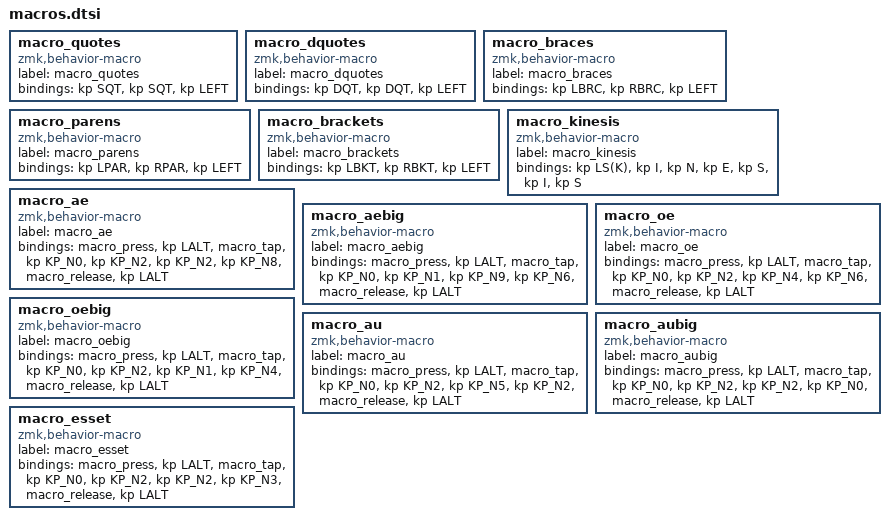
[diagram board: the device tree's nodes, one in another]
macro_quotes: macro_quotes{
compatible = "zmk,behavior-macro";
label = "macro_quotes";
#binding-cells = <0>;
bindings = <&kp SQT>, <&kp SQT>, <&kp LEFT>;
};
macro_dquotes: macro_dquotes{
compatible = "zmk,behavior-macro";
label = "macro_dquotes";
#binding-cells = <0>;
bindings = <&kp DQT>, <&kp DQT>, <&kp LEFT>;
};
macro_braces: macro_braces{
compatible = "zmk,behavior-macro";
label = "macro_braces";
#binding-cells = <0>;
bindings = <&kp LBRC>, <&kp RBRC>, <&kp LEFT>;
};
macro_parens: macro_parens{
compatible = "zmk,behavior-macro";
label = "macro_parens";
#binding-cells = <0>;
bindings = <&kp LPAR>, <&kp RPAR>, <&kp LEFT>;
};
macro_brackets: macro_brackets{
compatible = "zmk,behavior-macro";
label = "macro_brackets";
#binding-cells = <0>;
bindings = <&kp LBKT>, <&kp RBKT>, <&kp LEFT>;
};
macro_kinesis: macro_kinesis{
compatible = "zmk,behavior-macro";
label = "macro_kinesis";
#binding-cells = <0>;
bindings = <&kp LS(K)>, <&kp I>, <&kp N>, <&kp E>, <&kp S>, <&kp I>, <&kp S>;
};
macro_ae: macro_ae{
compatible = "zmk,behavior-macro";
label = "macro_ae";
#binding-cells = <0>;
bindings = <&macro_press &kp LALT>, <&macro_tap &kp KP_N0 &kp KP_N2 &kp KP_N2 &kp KP_N8>, <&macro_release &kp LALT>;
};
macro_aebig: macro_aebig{
compatible = "zmk,behavior-macro";
label = "macro_aebig";
#binding-cells = <0>;
bindings = <&macro_press &kp LALT>, <&macro_tap &kp KP_N0 &kp KP_N1 &kp KP_N9 &kp KP_N6>, <&macro_release &kp LALT>;
};
macro_oe: macro_oe{
compatible = "zmk,behavior-macro";
label = "macro_oe";
#binding-cells = <0>;
bindings = <&macro_press &kp LALT>, <&macro_tap &kp KP_N0 &kp KP_N2 &kp KP_N4 &kp KP_N6>, <&macro_release &kp LALT>;
};
macro_oebig: macro_oebig{
compatible = "zmk,behavior-macro";
label = "macro_oebig";
#binding-cells = <0>;
bindings = <&macro_press &kp LALT>, <&macro_tap &kp KP_N0 &kp KP_N2 &kp KP_N1 &kp KP_N4>, <&macro_release &kp LALT>;
};
macro_au: macro_au{
compatible = "zmk,behavior-macro";
label = "macro_au";
#binding-cells = <0>;
bindings = <&macro_press &kp LALT>, <&macro_tap &kp KP_N0 &kp KP_N2 &kp KP_N5 &kp KP_N2>, <&macro_release &kp LALT>;
};
macro_aubig: macro_aubig{
compatible = "zmk,behavior-macro";
label = "macro_aubig";
#binding-cells = <0>;
bindings = <&macro_press &kp LALT>, <&macro_tap &kp KP_N0 &kp KP_N2 &kp KP_N2 &kp KP_N0>, <&macro_release &kp LALT>;
};
macro_esset: macro_esset{
compatible = "zmk,behavior-macro";
label = "macro_esset";
#binding-cells = <0>;
bindings = <&macro_press &kp LALT>, <&macro_tap &kp KP_N0 &kp KP_N2 &kp KP_N2 &kp KP_N3>, <&macro_release &kp LALT>;
};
